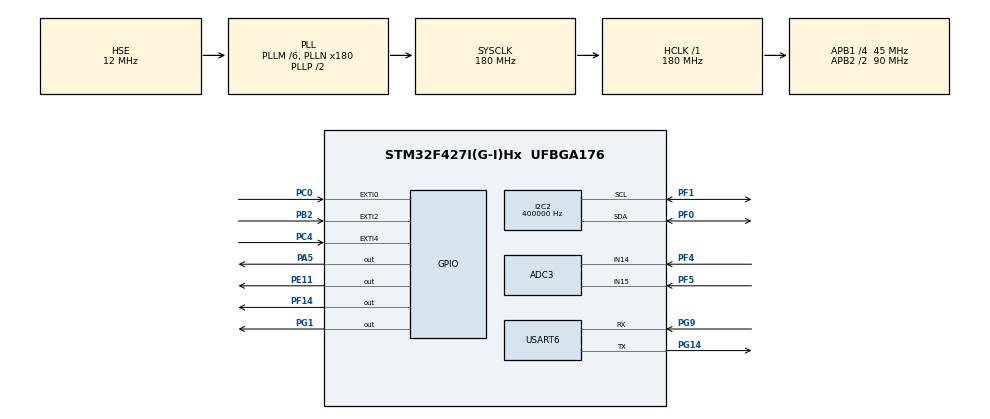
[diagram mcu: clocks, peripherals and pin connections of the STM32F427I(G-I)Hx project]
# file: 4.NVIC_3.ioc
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ADC3.Channel-0\#ChannelRegularConversion=ADC_CHANNEL_14
ADC3.NbrOfConversionFlag=1
ADC3.Rank-0\#ChannelRegularConversion=1
ADC3.SamplingTime-0\#ChannelRegularConversion=ADC_SAMPLETIME_3CYCLES
FREERTOS.Tasks01=defaultTask,0,128,StartDefaultTask,Default,NULL,Dynamic,NULL,NULL;myTask02,-3,128,StartTask02,Default,NULL,Dynamic,NULL,NULL
I2C2.ClockSpeed=400000
I2C2.DutyCycle=I2C_DUTYCYCLE_16_9
I2C2.I2C_Mode=I2C_Fast
Mcu.Family=STM32F4
Mcu.Name=STM32F427I(G-I)Hx
Mcu.Package=UFBGA176
NVIC.EXTI0_IRQn=true\:5\:0\:false\:false\:true\:false\:true\:true\:true
NVIC.EXTI2_IRQn=true\:5\:0\:false\:false\:true\:true\:true\:true\:true
NVIC.EXTI4_IRQn=true\:5\:0\:false\:false\:true\:true\:true\:true\:true
NVIC.I2C2_ER_IRQn=true\:5\:0\:false\:false\:true\:true\:true\:true\:true
NVIC.I2C2_EV_IRQn=true\:5\:0\:false\:false\:true\:true\:true\:true\:true
NVIC.PriorityGroup=NVIC_PRIORITYGROUP_4
PA13.Mode=Serial_Wire
PA13.Signal=SYS_JTMS-SWDIO
PA14.Mode=Serial_Wire
PA14.Signal=SYS_JTCK-SWCLK
PA5.Signal=GPIO_Output
PB2/BOOT1.GPIO_ModeDefaultEXTI=GPIO_MODE_IT_RISING
PB2/BOOT1.GPIO_PuPd=GPIO_PULLDOWN
PB2/BOOT1.Signal=GPXTI2
PC0.GPIO_PuPd=GPIO_PULLDOWN
PC0.Signal=GPXTI0
PC4.GPIO_ModeDefaultEXTI=GPIO_MODE_IT_FALLING
PC4.GPIO_PuPd=GPIO_PULLUP
PC4.Signal=GPXTI4
PE11.Signal=GPIO_Output
PF0.GPIO_Pu=GPIO_NOPULL
PF0.Mode=I2C
PF0.Signal=I2C2_SDA
PF1.GPIO_Pu=GPIO_NOPULL
PF1.Mode=I2C
PF1.Signal=I2C2_SCL
PF14.Signal=GPIO_Output
PF4.Mode=IN14
PF4.Signal=ADC3_IN14
PF5.Mode=IN15
PF5.Signal=ADC3_IN15
PG1.Signal=GPIO_Output
PG14.Mode=Asynchronous
PG14.Signal=USART6_TX
PG9.Mode=Asynchronous
PG9.Signal=USART6_RX
PH0/OSC_IN.Mode=HSE-External-Oscillator
PH0/OSC_IN.Signal=RCC_OSC_IN
PH1/OSC_OUT.Mode=HSE-External-Oscillator
PH1/OSC_OUT.Signal=RCC_OSC_OUT
ProjectManager.HeapSize=0x200
ProjectManager.StackSize=0x400
ProjectManager.TargetToolchain=MDK-ARM V5.32
RCC.48MHZClocksFreq_Value=90000000
RCC.AHBFreq_Value=180000000
RCC.APB1CLKDivider=RCC_HCLK_DIV4
RCC.APB1Freq_Value=45000000
RCC.APB1TimFreq_Value=90000000
RCC.APB2CLKDivider=RCC_HCLK_DIV2
RCC.APB2Freq_Value=90000000
RCC.APB2TimFreq_Value=180000000
RCC.CortexFreq_Value=180000000
RCC.HCLKFreq_Value=180000000
RCC.HSE_VALUE=12000000
RCC.HSI_VALUE=16000000
RCC.LSE_VALUE=32768
RCC.PLLM=6
RCC.PLLN=180
RCC.PLLSourceVirtual=RCC_PLLSOURCE_HSE
RCC.SYSCLKFreq_VALUE=180000000
RCC.SYSCLKSource=RCC_SYSCLKSOURCE_PLLCLK
RCC.VCOOutputFreq_Value=360000000
STMicroelectronics.X-CUBE-ALGOBUILD.1.4.0.LibraryCcDSPOoLibraryJjDSPOoLibrary=true
USART6.VirtualMode=VM_ASYNC
VP_FREERTOS_VS_CMSIS_V1.Mode=CMSIS_V1
VP_STMicroelectronics.X-CUBE-ALGOBUILD_VS_DSPOoLibraryJjLibrary_1.4.0_1.4.0.Mode=DSPOoLibraryJjLibrary
board=custom

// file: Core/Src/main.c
/* USER CODE BEGIN Header */
/**
  ******************************************************************************
  * @file           : main.c
  * @brief          : Main program body
  ******************************************************************************
  * @attention
  *
  * Copyright (c) 2025 STMicroelectronics.
  * All rights reserved.
  *
  * This software is licensed under terms that can be found in the LICENSE file
  * in the root directory of this software component.
  * If no LICENSE file comes with this software, it is provided AS-IS.
  *
  ******************************************************************************
  */
/* USER CODE END Header */
#include "main.h"
#include "cmsis_os.h"
#include "adc.h"
#include "i2c.h"
#include "usart.h"
#include "gpio.h"

/* USER CODE BEGIN Includes */
// -*- coding: utf-8 -*-
/* USER CODE END Includes */

void SystemClock_Config(void);
void MX_FREERTOS_Init(void);

int main(void)
{

  /* MCU Configuration--------------------------------------------------------*/

  /* Reset of all peripherals, Initializes the Flash interface and the Systick. */
  HAL_Init();

  /* Configure the system clock */
  SystemClock_Config();

  /* Initialize all configured peripherals */
  MX_GPIO_Init();
  MX_USART6_UART_Init();
  MX_I2C2_Init();
  MX_ADC3_Init();

  /* Call init function for freertos objects (in cmsis_os2.c) */
  MX_FREERTOS_Init();

  /* Start scheduler */
  osKernelStart();

  /* We should never get here as control is now taken by the scheduler */

  /* Infinite loop */
  while (1)
  {

  }
}

void SystemClock_Config(void)
{
  RCC_OscInitTypeDef RCC_OscInitStruct = {0};
  RCC_ClkInitTypeDef RCC_ClkInitStruct = {0};

  /** Configure the main internal regulator output voltage
  */
  __HAL_RCC_PWR_CLK_ENABLE();
  __HAL_PWR_VOLTAGESCALING_CONFIG(PWR_REGULATOR_VOLTAGE_SCALE1);

  /** Initializes the RCC Oscillators according to the specified parameters
  * in the RCC_OscInitTypeDef structure.
  */
  RCC_OscInitStruct.OscillatorType = RCC_OSCILLATORTYPE_HSE;
  RCC_OscInitStruct.HSEState = RCC_HSE_ON;
  RCC_OscInitStruct.PLL.PLLState = RCC_PLL_ON;
  RCC_OscInitStruct.PLL.PLLSource = RCC_PLLSOURCE_HSE;
  RCC_OscInitStruct.PLL.PLLM = 6;
  RCC_OscInitStruct.PLL.PLLN = 180;
  RCC_OscInitStruct.PLL.PLLP = RCC_PLLP_DIV2;
  RCC_OscInitStruct.PLL.PLLQ = 4;
  if (HAL_RCC_OscConfig(&RCC_OscInitStruct) != HAL_OK)
  {
    Error_Handler();
  }

  /** Activate the Over-Drive mode
  */
  if (HAL_PWREx_EnableOverDrive() != HAL_OK)
  {
    Error_Handler();
  }

  /** Initializes the CPU, AHB and APB buses clocks
  */
  RCC_ClkInitStruct.ClockType = RCC_CLOCKTYPE_HCLK|RCC_CLOCKTYPE_SYSCLK
                              |RCC_CLOCKTYPE_PCLK1|RCC_CLOCKTYPE_PCLK2;
  RCC_ClkInitStruct.SYSCLKSource = RCC_SYSCLKSOURCE_PLLCLK;
  RCC_ClkInitStruct.AHBCLKDivider = RCC_SYSCLK_DIV1;
  RCC_ClkInitStruct.APB1CLKDivider = RCC_HCLK_DIV4;
  RCC_ClkInitStruct.APB2CLKDivider = RCC_HCLK_DIV2;

  if (HAL_RCC_ClockConfig(&RCC_ClkInitStruct, FLASH_LATENCY_5) != HAL_OK)
  {
    Error_Handler();
  }
}

void Error_Handler(void)
{
  __disable_irq();
  while (1)
  {
  }
}

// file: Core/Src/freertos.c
/* USER CODE BEGIN Header */
/**
  ******************************************************************************
  * File Name          : freertos.c
  * Description        : Code for freertos applications
  ******************************************************************************
  * @attention
  *
  * Copyright (c) 2025 STMicroelectronics.
  * All rights reserved.
  *
  * This software is licensed under terms that can be found in the LICENSE file
  * in the root directory of this software component.
  * If no LICENSE file comes with this software, it is provided AS-IS.
  *
  ******************************************************************************
  */
/* USER CODE END Header */

#include "FreeRTOS.h"
#include "task.h"
#include "main.h"
#include "cmsis_os.h"

/* USER CODE BEGIN Includes */
#include "oledtask.h"
/* USER CODE END Includes */

/* USER CODE BEGIN PTD */
osThreadId oledTaskHandle;
/* USER CODE END PTD */

/* USER CODE BEGIN Variables */
osMutexDef(i2cMutex);                     // ���廥����
osMutexId i2cMutexHandle;                 // ��������������� osMutexId ���ͣ�
/* USER CODE END Variables */
osThreadId defaultTaskHandle;
osThreadId myTask02Handle;

void StartDefaultTask(void const * argument);
void StartTask02(void const * argument);

void MX_FREERTOS_Init(void); /* (MISRA C 2004 rule 8.1) */

/* GetIdleTaskMemory prototype (linked to static allocation support) */
void vApplicationGetIdleTaskMemory( StaticTask_t **ppxIdleTaskTCBBuffer, StackType_t **ppxIdleTaskStackBuffer, uint32_t *pulIdleTaskStackSize );

/* USER CODE BEGIN GET_IDLE_TASK_MEMORY */
static StaticTask_t xIdleTaskTCBBuffer;
static StackType_t xIdleStack[configMINIMAL_STACK_SIZE];

void vApplicationGetIdleTaskMemory( StaticTask_t **ppxIdleTaskTCBBuffer, StackType_t **ppxIdleTaskStackBuffer, uint32_t *pulIdleTaskStackSize )
{
  *ppxIdleTaskTCBBuffer = &xIdleTaskTCBBuffer;
  *ppxIdleTaskStackBuffer = &xIdleStack[0];
  *pulIdleTaskStackSize = configMINIMAL_STACK_SIZE;
  /* place for user code */
}
/* USER CODE END GET_IDLE_TASK_MEMORY */

void MX_FREERTOS_Init(void) {
  /* USER CODE BEGIN Init */
    i2cMutexHandle = osMutexCreate(osMutex(i2cMutex));  // ����������
    if (i2cMutexHandle == NULL) {
        Error_Handler();  // ����������ʧ��
    }
  /* USER CODE END Init */

  /* Create the thread(s) */
  /* definition and creation of defaultTask */
  osThreadDef(defaultTask, StartDefaultTask, osPriorityNormal, 0, 128);
  defaultTaskHandle = osThreadCreate(osThread(defaultTask), NULL);

  /* definition and creation of myTask02 */
  osThreadDef(myTask02, StartTask02, osPriorityIdle, 0, 128);
  myTask02Handle = osThreadCreate(osThread(myTask02), NULL);

  /* USER CODE BEGIN RTOS_THREADS */

				osThreadDef(oledTask, oled_task, osPriorityAboveNormal, 0, 128);
    oledTaskHandle = osThreadCreate(osThread(oledTask), NULL);
  /* add threads, ... */
  /* USER CODE END RTOS_THREADS */

}

void StartDefaultTask(void const * argument)
{
  for(;;)
  {
    osDelay(1);
  }
}

void StartTask02(void const * argument)
{
  for(;;)
  {
    osDelay(1);
  }
}
